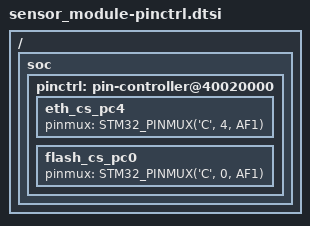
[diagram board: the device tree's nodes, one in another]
/ {
	soc {
		pinctrl: pin-controller@40020000 {
            eth_cs_pc4: eth_cs_pc4 {
                pinmux = <STM32_PINMUX('C', 4, AF1)>;
            };

            flash_cs_pc0: flash_cs_pc0 {
                pinmux = <STM32_PINMUX('C', 0, AF1)>;
            };
        };
    };
};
